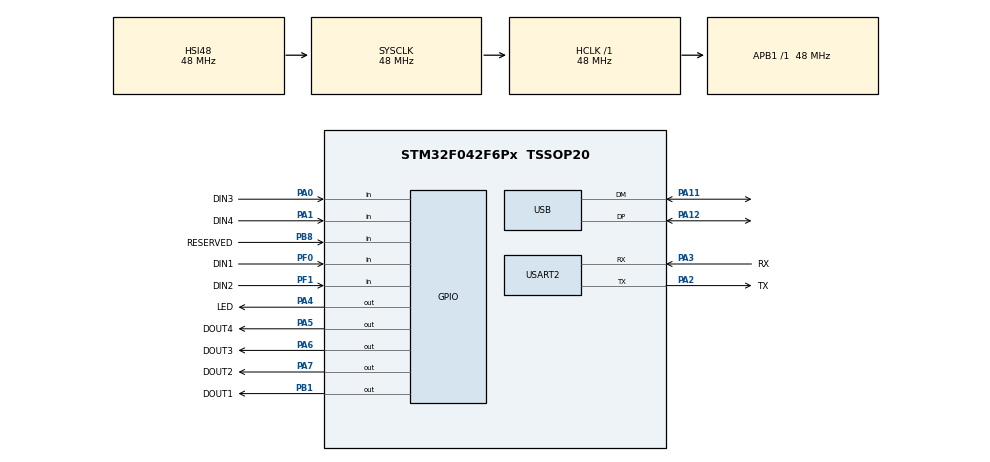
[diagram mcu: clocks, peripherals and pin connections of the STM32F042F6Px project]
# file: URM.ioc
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Mcu.Family=STM32F0
Mcu.Name=STM32F042F6Px
Mcu.Package=TSSOP20
NVIC.USB_IRQn=true\:0\:0\:false\:false\:true\:false\:true
PA0.GPIO_Label=DIN3
PA0.Signal=GPIO_Input
PA1.GPIO_Label=DIN4
PA1.Signal=GPIO_Input
PA11.Mode=Device
PA11.Signal=USB_DM
PA12.Mode=Device
PA12.Signal=USB_DP
PA13.Mode=Serial_Wire
PA13.Signal=SYS_SWDIO
PA14.Mode=Serial_Wire
PA14.Signal=SYS_SWCLK
PA2.GPIO_Label=TX
PA2.Mode=Asynchronous
PA2.Signal=USART2_TX
PA3.GPIO_Label=RX
PA3.Mode=Asynchronous
PA3.Signal=USART2_RX
PA4.GPIO_Label=LED
PA4.GPIO_ModeDefaultOutputPP=GPIO_MODE_OUTPUT_OD
PA4.PinState=GPIO_PIN_SET
PA4.Signal=GPIO_Output
PA5.GPIO_Label=DOUT4
PA5.Signal=GPIO_Output
PA6.GPIO_Label=DOUT3
PA6.Signal=GPIO_Output
PA7.GPIO_Label=DOUT2
PA7.Signal=GPIO_Output
PB1.GPIO_Label=DOUT1
PB1.Signal=GPIO_Output
PB8.GPIO_Label=RESERVED
PB8.Signal=GPIO_Input
PF0-OSC_IN.GPIO_Label=DIN1
PF0-OSC_IN.Signal=GPIO_Input
PF1-OSC_OUT.GPIO_Label=DIN2
PF1-OSC_OUT.Signal=GPIO_Input
ProjectManager.HeapSize=0x200
ProjectManager.StackSize=0x400
ProjectManager.TargetToolchain=STM32CubeIDE
RCC.AHBFreq_Value=48000000
RCC.APB1Freq_Value=48000000
RCC.APB1TimFreq_Value=48000000
RCC.HCLKFreq_Value=48000000
RCC.SYSCLKFreq_VALUE=48000000
RCC.SYSCLKSource=RCC_SYSCLKSOURCE_HSI48
USART2.VirtualMode-Asynchronous=VM_ASYNC
USB_DEVICE.CLASS_NAME_FS=CUSTOM_HID
USB_DEVICE.VirtualMode=CustomHid
USB_DEVICE.VirtualModeFS=Custom_Hid_FS
VP_SYS_VS_PINREMAP.Mode=PINREMAP
VP_USB_DEVICE_VS_USB_DEVICE_CUSTOM_HID_FS.Mode=CUSTOM_HID_FS
board=custom

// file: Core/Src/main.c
/* USER CODE BEGIN Header */
/**
  ******************************************************************************
  * @file           : main.c
  * @brief          : Main program body
  ******************************************************************************
  * @attention
  *
  * <h2><center>&copy; Copyright (c) 2021 STMicroelectronics.
  * All rights reserved.</center></h2>
  *
  * This software component is licensed by ST under BSD 3-Clause license,
  * the "License"; You may not use this file except in compliance with the
  * License. You may obtain a copy of the License at:
  *                        opensource.org/licenses/BSD-3-Clause
  *
  ******************************************************************************
  */
/* USER CODE END Header */

#include "main.h"
#include "usb_device.h"

/* USER CODE BEGIN Includes */
#include "appMain.h"
/* USER CODE END Includes */

UART_HandleTypeDef huart2;

void SystemClock_Config(void);
static void MX_GPIO_Init(void);
static void MX_USART2_UART_Init(void);

int main(void)
{
  /* USER CODE BEGIN 1 */
  ApplicationBoot();
  /* USER CODE END 1 */

  /* MCU Configuration--------------------------------------------------------*/

  /* Reset of all peripherals, Initializes the Flash interface and the Systick. */
  HAL_Init();

  /* Configure the system clock */
  SystemClock_Config();

  /* Initialize all configured peripherals */
  MX_GPIO_Init();
  MX_USART2_UART_Init();
  MX_USB_DEVICE_Init();
  /* USER CODE BEGIN 2 */
    ApplicationInit();
  /* USER CODE END 2 */

  /* Infinite loop */
  while (1)
  {
    ApplicationLoop();
  }
}

void SystemClock_Config(void)
{
  RCC_OscInitTypeDef RCC_OscInitStruct = {0};
  RCC_ClkInitTypeDef RCC_ClkInitStruct = {0};
  RCC_PeriphCLKInitTypeDef PeriphClkInit = {0};

  /** Initializes the CPU, AHB and APB busses clocks
  */
  RCC_OscInitStruct.OscillatorType = RCC_OSCILLATORTYPE_HSI48;
  RCC_OscInitStruct.HSI48State = RCC_HSI48_ON;
  RCC_OscInitStruct.PLL.PLLState = RCC_PLL_NONE;
  if (HAL_RCC_OscConfig(&RCC_OscInitStruct) != HAL_OK)
  {
    Error_Handler();
  }
  /** Initializes the CPU, AHB and APB busses clocks
  */
  RCC_ClkInitStruct.ClockType = RCC_CLOCKTYPE_HCLK|RCC_CLOCKTYPE_SYSCLK
                              |RCC_CLOCKTYPE_PCLK1;
  RCC_ClkInitStruct.SYSCLKSource = RCC_SYSCLKSOURCE_HSI48;
  RCC_ClkInitStruct.AHBCLKDivider = RCC_SYSCLK_DIV1;
  RCC_ClkInitStruct.APB1CLKDivider = RCC_HCLK_DIV1;

  if (HAL_RCC_ClockConfig(&RCC_ClkInitStruct, FLASH_LATENCY_1) != HAL_OK)
  {
    Error_Handler();
  }
  PeriphClkInit.PeriphClockSelection = RCC_PERIPHCLK_USB;
  PeriphClkInit.UsbClockSelection = RCC_USBCLKSOURCE_HSI48;

  if (HAL_RCCEx_PeriphCLKConfig(&PeriphClkInit) != HAL_OK)
  {
    Error_Handler();
  }
}

static void MX_USART2_UART_Init(void)
{

  huart2.Instance = USART2;
  huart2.Init.BaudRate = 38400;
  huart2.Init.WordLength = UART_WORDLENGTH_8B;
  huart2.Init.StopBits = UART_STOPBITS_1;
  huart2.Init.Parity = UART_PARITY_NONE;
  huart2.Init.Mode = UART_MODE_TX_RX;
  huart2.Init.HwFlowCtl = UART_HWCONTROL_NONE;
  huart2.Init.OverSampling = UART_OVERSAMPLING_16;
  huart2.Init.OneBitSampling = UART_ONE_BIT_SAMPLE_DISABLE;
  huart2.AdvancedInit.AdvFeatureInit = UART_ADVFEATURE_NO_INIT;
  if (HAL_UART_Init(&huart2) != HAL_OK)
  {
    Error_Handler();
  }

}

static void MX_GPIO_Init(void)
{
  GPIO_InitTypeDef GPIO_InitStruct = {0};

  /* GPIO Ports Clock Enable */
  __HAL_RCC_GPIOB_CLK_ENABLE();
  __HAL_RCC_GPIOF_CLK_ENABLE();
  __HAL_RCC_GPIOA_CLK_ENABLE();

  /*Configure GPIO pin Output Level */
  HAL_GPIO_WritePin(LED_GPIO_Port, LED_Pin, GPIO_PIN_SET);

  /*Configure GPIO pin Output Level */
  HAL_GPIO_WritePin(GPIOA, DOUT4_Pin|DOUT3_Pin|DOUT2_Pin, GPIO_PIN_RESET);

  /*Configure GPIO pin Output Level */
  HAL_GPIO_WritePin(DOUT1_GPIO_Port, DOUT1_Pin, GPIO_PIN_RESET);

  /*Configure GPIO pin : RESERVED_Pin */
  GPIO_InitStruct.Pin = RESERVED_Pin;
  GPIO_InitStruct.Mode = GPIO_MODE_INPUT;
  GPIO_InitStruct.Pull = GPIO_NOPULL;
  HAL_GPIO_Init(RESERVED_GPIO_Port, &GPIO_InitStruct);

  /*Configure GPIO pins : DIN1_Pin DIN2_Pin */
  GPIO_InitStruct.Pin = DIN1_Pin|DIN2_Pin;
  GPIO_InitStruct.Mode = GPIO_MODE_INPUT;
  GPIO_InitStruct.Pull = GPIO_NOPULL;
  HAL_GPIO_Init(GPIOF, &GPIO_InitStruct);

  /*Configure GPIO pins : DIN3_Pin DIN4_Pin */
  GPIO_InitStruct.Pin = DIN3_Pin|DIN4_Pin;
  GPIO_InitStruct.Mode = GPIO_MODE_INPUT;
  GPIO_InitStruct.Pull = GPIO_NOPULL;
  HAL_GPIO_Init(GPIOA, &GPIO_InitStruct);

  /*Configure GPIO pin : LED_Pin */
  GPIO_InitStruct.Pin = LED_Pin;
  GPIO_InitStruct.Mode = GPIO_MODE_OUTPUT_OD;
  GPIO_InitStruct.Pull = GPIO_NOPULL;
  GPIO_InitStruct.Speed = GPIO_SPEED_FREQ_LOW;
  HAL_GPIO_Init(LED_GPIO_Port, &GPIO_InitStruct);

  /*Configure GPIO pins : DOUT4_Pin DOUT3_Pin DOUT2_Pin */
  GPIO_InitStruct.Pin = DOUT4_Pin|DOUT3_Pin|DOUT2_Pin;
  GPIO_InitStruct.Mode = GPIO_MODE_OUTPUT_PP;
  GPIO_InitStruct.Pull = GPIO_NOPULL;
  GPIO_InitStruct.Speed = GPIO_SPEED_FREQ_LOW;
  HAL_GPIO_Init(GPIOA, &GPIO_InitStruct);

  /*Configure GPIO pin : DOUT1_Pin */
  GPIO_InitStruct.Pin = DOUT1_Pin;
  GPIO_InitStruct.Mode = GPIO_MODE_OUTPUT_PP;
  GPIO_InitStruct.Pull = GPIO_NOPULL;
  GPIO_InitStruct.Speed = GPIO_SPEED_FREQ_LOW;
  HAL_GPIO_Init(DOUT1_GPIO_Port, &GPIO_InitStruct);

}

void Error_Handler(void)
{
}

/************************ (C) COPYRIGHT STMicroelectronics *****END OF FILE****/
